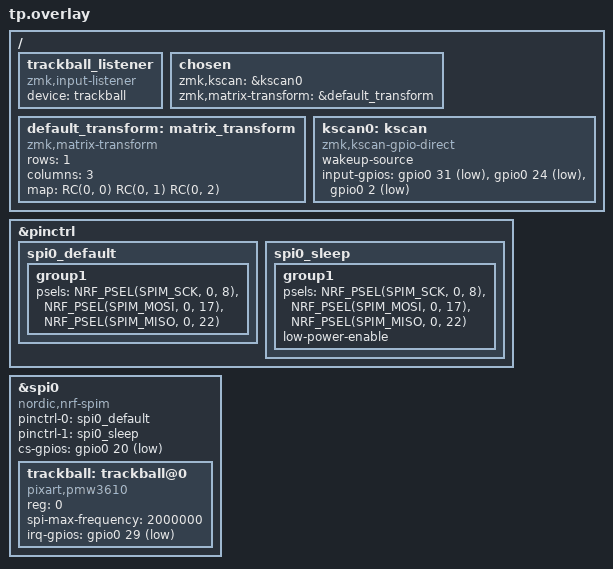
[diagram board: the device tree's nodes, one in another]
#include "tp-layouts.dtsi"
#include <dt-bindings/zmk/matrix_transform.h>

&pinctrl {
    spi0_default: spi0_default {
        group1 {
            psels = <NRF_PSEL(SPIM_SCK, 0, 8)>,
                <NRF_PSEL(SPIM_MOSI, 0, 17)>,
                <NRF_PSEL(SPIM_MISO, 0, 22)>;
        };
    };

    spi0_sleep: spi0_sleep {
        group1 {
            psels = <NRF_PSEL(SPIM_SCK, 0, 8)>,
                <NRF_PSEL(SPIM_MOSI, 0, 17)>,
                <NRF_PSEL(SPIM_MISO, 0, 22)>;
            low-power-enable;
        };
    };
};

&spi0 {
    status = "okay";
    compatible = "nordic,nrf-spim";
    pinctrl-0 = <&spi0_default>;
    pinctrl-1 = <&spi0_sleep>;
    pinctrl-names = "default", "sleep";
    cs-gpios = <&gpio0 20 GPIO_ACTIVE_LOW>;

    trackball: trackball@0 {
        status = "okay";
        compatible = "pixart,pmw3610";
        reg = <0>;
        spi-max-frequency = <2000000>;
        irq-gpios = <&gpio0 29 (GPIO_ACTIVE_LOW | GPIO_PULL_UP)>;

        /*   optional features   */
        // snipe-layers = <1>;
        // scroll-layers = <2 3>;
        // automouse-layer = <4>;
    };
};

/ {
  trackball_listener {
    compatible = "zmk,input-listener";
    device = <&trackball>;

  };
};

/ {
    chosen {
        zmk,kscan = &kscan0;
        zmk,matrix-transform = &default_transform;
    };

    default_transform: matrix_transform {
        compatible = "zmk,matrix-transform";
        rows = <1>;
        columns = <3>;

        map = <
            RC(0, 0) RC(0, 1) RC(0, 2)
        >; 
    };

    kscan0: kscan {
        compatible = "zmk,kscan-gpio-direct";
        wakeup-source;

        input-gpios = <&gpio0 31 (GPIO_ACTIVE_LOW | GPIO_PULL_UP)>,
                    <&gpio0 24 (GPIO_ACTIVE_LOW | GPIO_PULL_UP)>,
                    <&gpio0 2 (GPIO_ACTIVE_LOW | GPIO_PULL_UP)>;

        
    };
};
